# STM32G474xx register map
File version: 1.6
CPU: CM4 r0p1, little endian, MPU, FPU, 4 interrupt priority bits
Registers are 32-bit, read-write, reset 0x0 unless marked. A register's access mark holds for its fields unless they carry their own. Offsets are from the block's base; [hi:lo] are bit positions; {n}, {i} and the like mark numbered series; 'fields as' and 'values as' point back to an identical list.

## HRTIM_Common — High Resolution Timer: Common functions
Base 0x40016B80
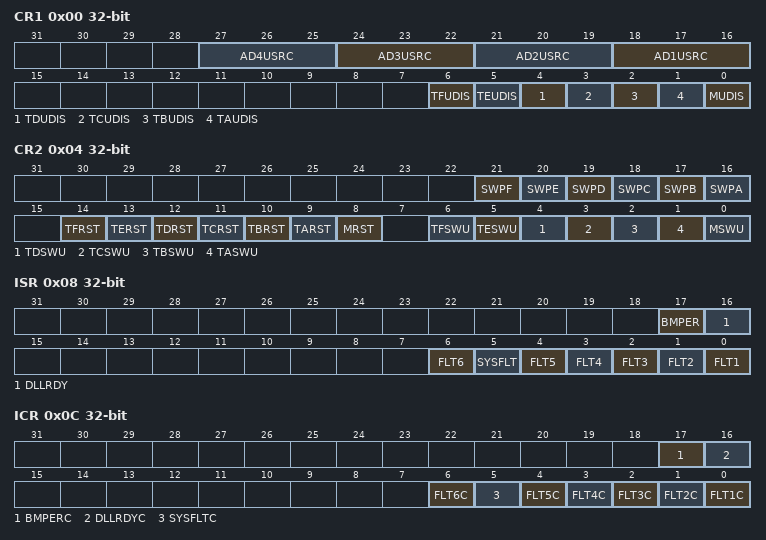
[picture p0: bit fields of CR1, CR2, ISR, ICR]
0x00 CR1 — Control Register 1
  [3n+15:3n+13] AD{n}USRC (n=1..4) — ADC Trigger {n} Update Source
  [6] TFUDIS — Timer f Update Disable
  [5] TEUDIS — Timer E Update Disable
  [4] TDUDIS — Timer D Update Disable
  [3] TCUDIS — Timer C Update Disable
  [2] TBUDIS — Timer B Update Disable
  [1] TAUDIS — Timer A Update Disable
  [0] MUDIS — Master Update Disable
0x04 CR2 — Control Register 2
  [21] SWPF — Swap Timer F outputs
  [20] SWPE — Swap Timer E outputs
  [19] SWPD — Swap Timer D outputs
  [18] SWPC — Swap Timer C outputs
  [17] SWPB — Swap Timer B outputs
  [16] SWPA — Swap Timer A outputs
  [14] TFRST — Timer f counter software reset
  [13] TERST — Timer E counter software reset
  [12] TDRST — Timer D counter software reset
  [11] TCRST — Timer C counter software reset
  [10] TBRST — Timer B counter software reset
  [9] TARST — Timer A counter software reset
  [8] MRST — Master Counter software reset
  [6] TFSWU — Timer f Software Update
  [5] TESWU — Timer E Software Update
  [4] TDSWU — Timer D Software Update
  [3] TCSWU — Timer C Software Update
  [2] TBSWU — Timer B Software Update
  [1] TASWU — Timer A Software update
  [0] MSWU — Master Timer Software update
0x08 ISR ro — Interrupt Status Register
  [17] BMPER — Burst mode Period Interrupt Flag
  [16] DLLRDY — DLL Ready Interrupt Flag
  [6] FLT6 — Fault 6 Interrupt Flag
  [5] SYSFLT — System Fault Interrupt Flag
  [n-1] FLT{n} (n=1..5) — Fault {n} Interrupt Flag
0x0C ICR wo — Interrupt Clear Register
  [17] BMPERC — Burst mode period flag Clear
  [16] DLLRDYC — DLL Ready Interrupt flag Clear
  [6] FLT6C — Fault 6 Interrupt Flag Clear
  [5] SYSFLTC — System Fault Interrupt Flag Clear
  [n-1] FLT{n}C (n=1..5) — Fault {n} Interrupt Flag Clear
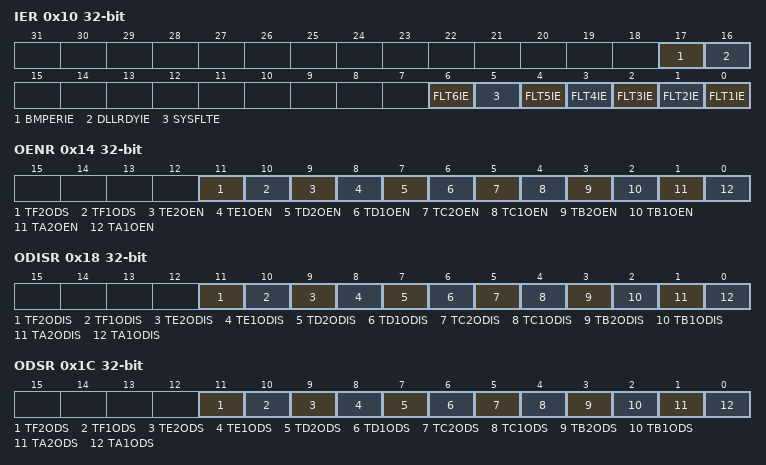
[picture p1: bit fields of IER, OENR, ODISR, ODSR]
0x10 IER — Interrupt Enable Register
  [17] BMPERIE — Burst mode period Interrupt Enable
  [16] DLLRDYIE — DLL Ready Interrupt Enable
  [6] FLT6IE — Fault 6 Interrupt Enable
  [5] SYSFLTE — System Fault Interrupt Enable
  [n-1] FLT{n}IE (n=1..5) — Fault {n} Interrupt Enable
0x14 OENR — Output Enable Register
  [11] TF2ODS — Timer F Output 2 disable status
  [10] TF1ODS — Timer F Output 1 disable status
  [9] TE2OEN — Timer E Output 2 Enable
  [8] TE1OEN — Timer E Output 1 Enable
  [7] TD2OEN — Timer D Output 2 Enable
  [6] TD1OEN — Timer D Output 1 Enable
  [5] TC2OEN — Timer C Output 2 Enable
  [4] TC1OEN — Timer C Output 1 Enable
  [3] TB2OEN — Timer B Output 2 Enable
  [2] TB1OEN — Timer B Output 1 Enable
  [1] TA2OEN — Timer A Output 2 Enable
  [0] TA1OEN — Timer A Output 1 Enable
0x18 ODISR wo
  [11] TF2ODIS, [10] TF1ODIS, [9] TE2ODIS, [8] TE1ODIS, [7] TD2ODIS, [6] TD1ODIS, [5] TC2ODIS, [4] TC1ODIS, [3] TB2ODIS, [2] TB1ODIS, [1] TA2ODIS, [0] TA1ODIS
0x1C ODSR ro — Output Disable Status Register
  [11] TF2ODS
  [10] TF1ODS
  [9] TE2ODS — Timer E Output 2 disable status
  [8] TE1ODS — Timer E Output 1 disable status
  [7] TD2ODS — Timer D Output 2 disable status
  [6] TD1ODS — Timer D Output 1 disable status
  [5] TC2ODS — Timer C Output 2 disable status
  [4] TC1ODS — Timer C Output 1 disable status
  [3] TB2ODS — Timer B Output 2 disable status
  [2] TB1ODS — Timer B Output 1 disable status
  [1] TA2ODS — Timer A Output 2 disable status
  [0] TA1ODS — Timer A Output 1 disable status
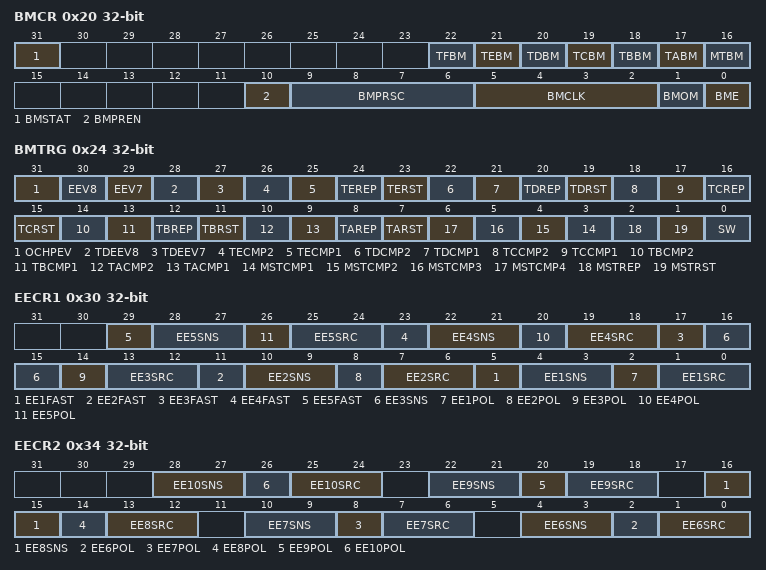
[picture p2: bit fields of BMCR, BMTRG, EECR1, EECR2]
0x20 BMCR — Burst Mode Control Register
  [31] BMSTAT — Burst Mode Status
  [22] TFBM — Timer f Burst Mode
  [21] TEBM — Timer E Burst Mode
  [20] TDBM — Timer D Burst Mode
  [19] TCBM — Timer C Burst Mode
  [18] TBBM — Timer B Burst Mode
  [17] TABM — Timer A Burst Mode
  [16] MTBM — Master Timer Burst Mode
  [10] BMPREN — Burst Mode Preload Enable
  [9:6] BMPRSC — Burst Mode Prescaler
  [5:2] BMCLK — Burst Mode Clock source
  [1] BMOM — Burst Mode operating mode
  [0] BME — Burst Mode enable
0x24 BMTRG
  [31] OCHPEV, [30] EEV8, [29] EEV7, [28] TDEEV8, [27] TDEEV7, [26] TECMP2, [25] TECMP1, [24] TEREP, [23] TERST, [22] TDCMP2, [21] TDCMP1, [20] TDREP, [19] TDRST, [18] TCCMP2, [17] TCCMP1, [16] TCREP, [15] TCRST, [14] TBCMP2, [13] TBCMP1, [12] TBREP, [11] TBRST, [10] TACMP2, [9] TACMP1, [8] TAREP, [7] TARST, [n+2] MSTCMP{n} (n=1..4), [2] MSTREP, [1] MSTRST, [0] SW
0x28 BMCMPR
  [15:0] BMCMP
0x2C BMPER — Burst Mode Period Register
  [15:0] BMPER — Burst mode Period
0x30 EECR1 — Timer External Event Control Register 1
  [6n-1] EE{n}FAST (n=1..5) — External Event {n} Fast mode
  [6n-2:6n-3] EE{n}SNS (n=1..5) — External Event {n} Sensitivity
  [6n-4] EE{n}POL (n=1..5) — External Event {n} Polarity
  [6n-5:6n-6] EE{n}SRC (n=1..5) — External Event {n} Source
0x34 EECR2 — Timer External Event Control Register 2
  [6n-32:6n-33] EE{n}SNS (n=6..10), [6n-34] EE{n}POL (n=6..10), [6n-35:6n-36] EE{n}SRC (n=6..10)
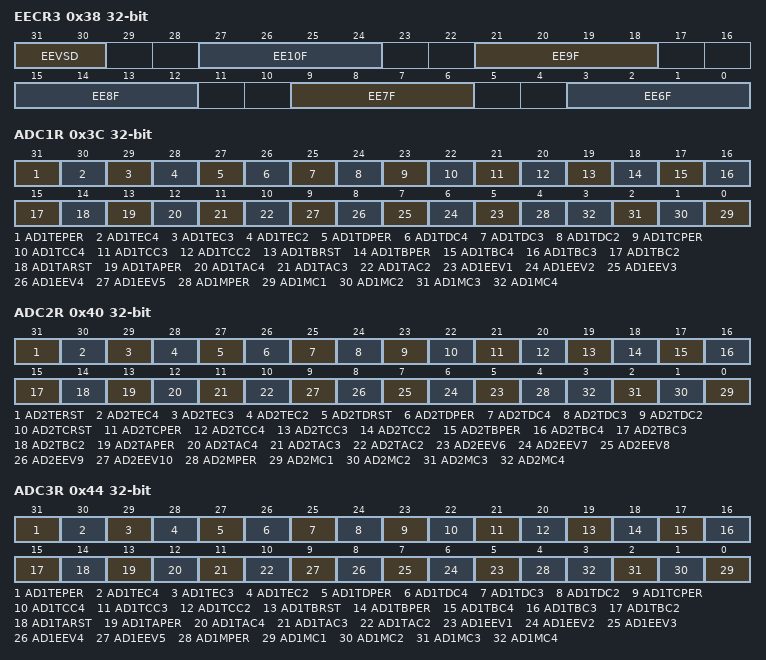
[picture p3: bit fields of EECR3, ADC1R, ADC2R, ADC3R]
0x38 EECR3 — Timer External Event Control Register 3
  [31:30] EEVSD, [6n-33:6n-36] EE{n}F (n=6..10)
0x3C ADC1R — ADC Trigger 1 Register
  [31] AD1TEPER — ADC trigger 1 on Timer E Period
  [30] AD1TEC4 — ADC trigger 1 on Timer E compare 4
  [29] AD1TEC3 — ADC trigger 1 on Timer E compare 3
  [28] AD1TEC2 — ADC trigger 1 on Timer E compare 2
  [27] AD1TDPER — ADC trigger 1 on Timer D Period
  [26] AD1TDC4 — ADC trigger 1 on Timer D compare 4
  [25] AD1TDC3 — ADC trigger 1 on Timer D compare 3
  [24] AD1TDC2 — ADC trigger 1 on Timer D compare 2
  [23] AD1TCPER — ADC trigger 1 on Timer C Period
  [22] AD1TCC4 — ADC trigger 1 on Timer C compare 4
  [21] AD1TCC3 — ADC trigger 1 on Timer C compare 3
  [20] AD1TCC2 — ADC trigger 1 on Timer C compare 2
  [19] AD1TBRST — ADC trigger 1 on Timer B Reset
  [18] AD1TBPER — ADC trigger 1 on Timer B Period
  [17] AD1TBC4 — ADC trigger 1 on Timer B compare 4
  [16] AD1TBC3 — ADC trigger 1 on Timer B compare 3
  [15] AD1TBC2 — ADC trigger 1 on Timer B compare 2
  [14] AD1TARST — ADC trigger 1 on Timer A Reset
  [13] AD1TAPER — ADC trigger 1 on Timer A Period
  [12] AD1TAC4 — ADC trigger 1 on Timer A compare 4
  [11] AD1TAC3 — ADC trigger 1 on Timer A compare 3
  [10] AD1TAC2 — ADC trigger 1 on Timer A compare 2
  [n+4] AD1EEV{n} (n=1..5) — ADC trigger 1 on External Event {n}
  [4] AD1MPER — ADC trigger 1 on Master Period
  [n-1] AD1MC{n} (n=1..4) — ADC trigger 1 on Master Compare {n}
0x40 ADC2R — ADC Trigger 2 Register
  [31] AD2TERST — ADC trigger 2 on Timer E Reset
  [30] AD2TEC4 — ADC trigger 2 on Timer E compare 4
  [29] AD2TEC3 — ADC trigger 2 on Timer E compare 3
  [28] AD2TEC2 — ADC trigger 2 on Timer E compare 2
  [27] AD2TDRST — ADC trigger 2 on Timer D Reset
  [26] AD2TDPER — ADC trigger 2 on Timer D Period
  [25] AD2TDC4 — ADC trigger 2 on Timer D compare 4
  [24] AD2TDC3 — ADC trigger 2 on Timer D compare 3
  [23] AD2TDC2 — ADC trigger 2 on Timer D compare 2
  [22] AD2TCRST — ADC trigger 2 on Timer C Reset
  [21] AD2TCPER — ADC trigger 2 on Timer C Period
  [20] AD2TCC4 — ADC trigger 2 on Timer C compare 4
  [19] AD2TCC3 — ADC trigger 2 on Timer C compare 3
  [18] AD2TCC2 — ADC trigger 2 on Timer C compare 2
  [17] AD2TBPER — ADC trigger 2 on Timer B Period
  [16] AD2TBC4 — ADC trigger 2 on Timer B compare 4
  [15] AD2TBC3 — ADC trigger 2 on Timer B compare 3
  [14] AD2TBC2 — ADC trigger 2 on Timer B compare 2
  [13] AD2TAPER — ADC trigger 2 on Timer A Period
  [12] AD2TAC4 — ADC trigger 2 on Timer A compare 4
  [11] AD2TAC3 — ADC trigger 2 on Timer A compare 3
  [10] AD2TAC2 — ADC trigger 2 on Timer A compare 2
  [n-1] AD2EEV{n} (n=6..10) — ADC trigger 2 on External Event {n}
  [4] AD2MPER — ADC trigger 2 on Master Period
  [n-1] AD2MC{n} (n=1..4) — ADC trigger 2 on Master Compare {n}
0x44 ADC3R — ADC Trigger 3 Register
  [31] AD1TEPER, [30] AD1TEC4, [29] AD1TEC3, [28] AD1TEC2, [27] AD1TDPER, [26] AD1TDC4, [25] AD1TDC3, [24] AD1TDC2, [23] AD1TCPER, [22] AD1TCC4, [21] AD1TCC3, [20] AD1TCC2, [19] AD1TBRST, [18] AD1TBPER, [17] AD1TBC4, [16] AD1TBC3, [15] AD1TBC2, [14] AD1TARST, [13] AD1TAPER, [12] AD1TAC4, [11] AD1TAC3, [10] AD1TAC2, [n+4] AD1EEV{n} (n=1..5), [4] AD1MPER, [n-1] AD1MC{n} (n=1..4)
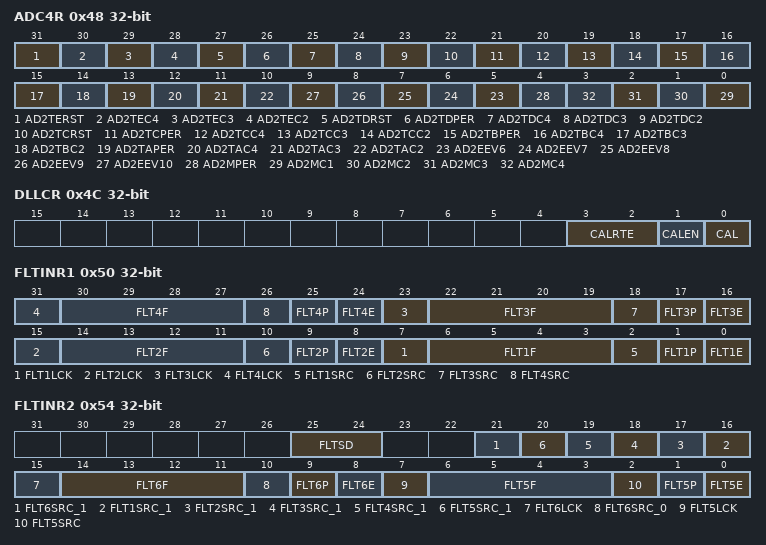
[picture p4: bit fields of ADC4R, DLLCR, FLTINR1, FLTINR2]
0x48 ADC4R — ADC Trigger 4 Register
  [31] AD2TERST, [30] AD2TEC4, [29] AD2TEC3, [28] AD2TEC2, [27] AD2TDRST, [26] AD2TDPER, [25] AD2TDC4, [24] AD2TDC3, [23] AD2TDC2, [22] AD2TCRST, [21] AD2TCPER, [20] AD2TCC4, [19] AD2TCC3, [18] AD2TCC2, [17] AD2TBPER, [16] AD2TBC4, [15] AD2TBC3, [14] AD2TBC2, [13] AD2TAPER, [12] AD2TAC4, [11] AD2TAC3, [10] AD2TAC2, [n-1] AD2EEV{n} (n=6..10), [4] AD2MPER, [n-1] AD2MC{n} (n=1..4)
0x4C DLLCR — DLL Control Register
  [3:2] CALRTE — DLL Calibration rate
  [1] CALEN — DLL Calibration Enable
  [0] CAL — DLL Calibration Start
0x50 FLTINR1 — HRTIM Fault Input Register 1
  [8n-1] FLT{n}LCK (n=1..4), [8n-2:8n-5] FLT{n}F (n=1..4), [8n-6] FLT{n}SRC (n=1..4), [8n-7] FLT{n}P (n=1..4), [8n-8] FLT{n}E (n=1..4)
0x54 FLTINR2 — HRTIM Fault Input Register 2
  [25:24] FLTSD
  [21] FLT6SRC_1 — FLT6SRC
  [n+15] FLT{n}SRC_1 (n=1..5)
  [15] FLT6LCK
  [14:11] FLT6F
  [10] FLT6SRC_0 — FLT6F
  [9] FLT6P
  [8] FLT6E
  [7] FLT5LCK
  [6:3] FLT5F
  [2] FLT5SRC
  [1] FLT5P
  [0] FLT5E
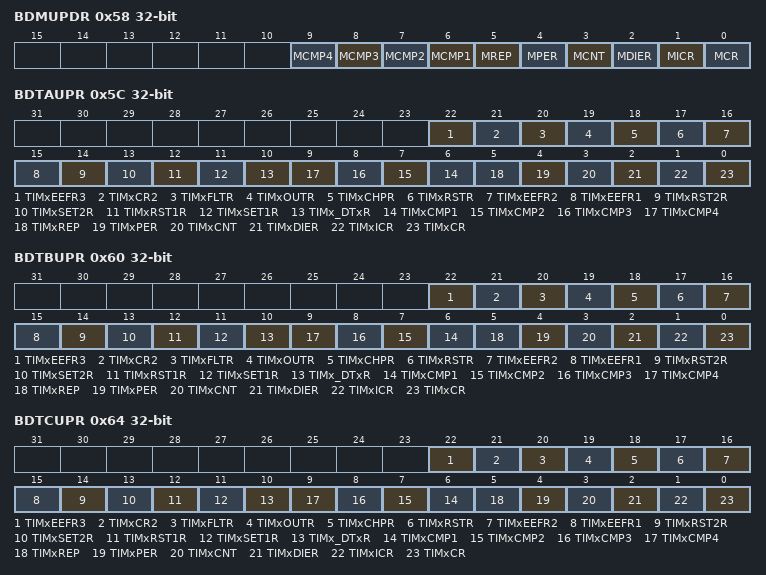
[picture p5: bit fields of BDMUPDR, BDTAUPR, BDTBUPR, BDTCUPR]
0x58 BDMUPDR
  [n+5] MCMP{n} (n=1..4), [5] MREP, [4] MPER, [3] MCNT, [2] MDIER, [1] MICR, [0] MCR
0x5C BDTAUPR — Burst DMA Timerx update Register
  [22] TIMxEEFR3
  [21] TIMxCR2
  [20] TIMxFLTR — HRTIM_FLTxR register update enable
  [19] TIMxOUTR — HRTIM_OUTxR register update enable
  [18] TIMxCHPR — HRTIM_CHPxR register update enable
  [17] TIMxRSTR — HRTIM_RSTxR register update enable
  [16] TIMxEEFR2 — HRTIM_EEFxR2 register update enable
  [15] TIMxEEFR1 — HRTIM_EEFxR1 register update enable
  [14] TIMxRST2R — HRTIM_RST2xR register update enable
  [13] TIMxSET2R — HRTIM_SET2xR register update enable
  [12] TIMxRST1R — HRTIM_RST1xR register update enable
  [11] TIMxSET1R — HRTIM_SET1xR register update enable
  [10] TIMx_DTxR — HRTIM_DTxR register update enable
  [n+5] TIMxCMP{n} (n=1..4) — HRTIM_CMP{n}xR register update enable
  [5] TIMxREP — HRTIM_REPxR register update enable
  [4] TIMxPER — HRTIM_PERxR register update enable
  [3] TIMxCNT — HRTIM_CNTxR register update enable
  [2] TIMxDIER — HRTIM_TIMxDIER register update enable
  [1] TIMxICR — HRTIM_TIMxICR register update enable
  [0] TIMxCR — HRTIM_TIMxCR register update enable
0x60 BDTBUPR — Burst DMA Timerx update Register
  fields as BDTAUPR
0x64 BDTCUPR — Burst DMA Timerx update Register
  fields as BDTAUPR
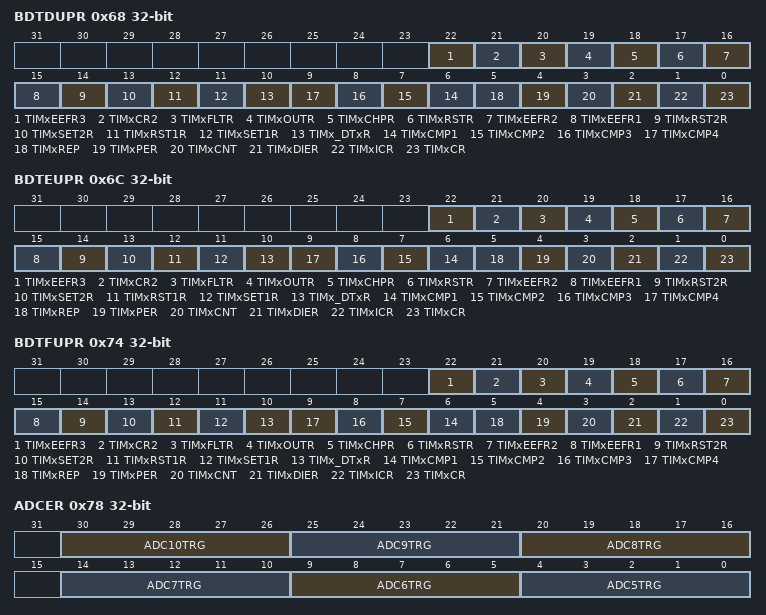
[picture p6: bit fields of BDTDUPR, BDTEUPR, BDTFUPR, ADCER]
0x68 BDTDUPR — Burst DMA Timerx update Register
  fields as BDTAUPR
0x6C BDTEUPR — Burst DMA Timerx update Register
  fields as BDTAUPR
0x70 BDMADR wo — Burst DMA Data Register
  [31:0] BDMADR — Burst DMA Data register
0x74 BDTFUPR — Burst DMA Timerx update Register
  fields as BDTAUPR
0x78 ADCER — HRTIM ADC Extended Trigger Register
  [30:26] ADC10TRG, [25:21] ADC9TRG, [20:16] ADC8TRG, [14:10] ADC7TRG, [9:5] ADC6TRG, [4:0] ADC5TRG
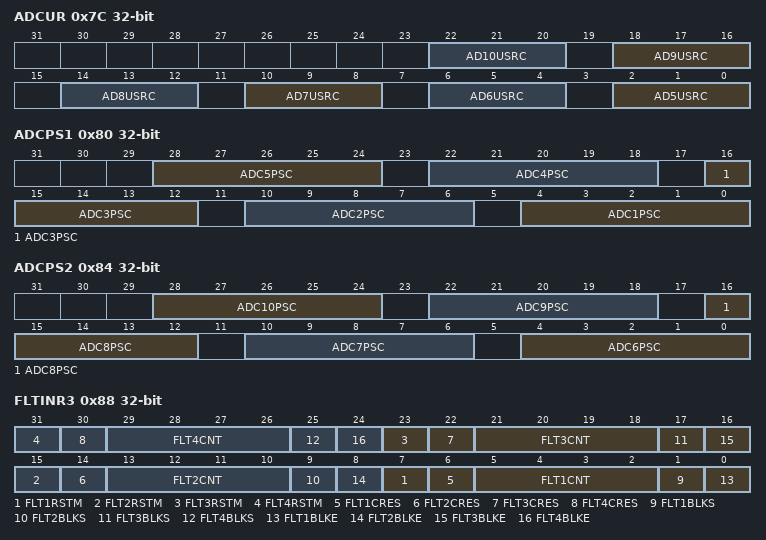
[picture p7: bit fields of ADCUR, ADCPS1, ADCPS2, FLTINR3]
0x7C ADCUR — HRTIM ADC Trigger Update Register
  [4n-18:4n-20] AD{n}USRC (n=5..10)
0x80 ADCPS1 — HRTIM ADC Post Scaler Register 1
  [6n-2:6n-6] ADC{n}PSC (n=1..5)
0x84 ADCPS2 — HRTIM ADC Post Scaler Register 2
  [6n-32:6n-36] ADC{n}PSC (n=6..10)
0x88 FLTINR3 — HRTIM Fault Input Register 3
  [8n-1] FLT{n}RSTM (n=1..4), [8n-2] FLT{n}CRES (n=1..4), [8n-3:8n-6] FLT{n}CNT (n=1..4), [8n-7] FLT{n}BLKS (n=1..4), [8n-8] FLT{n}BLKE (n=1..4)
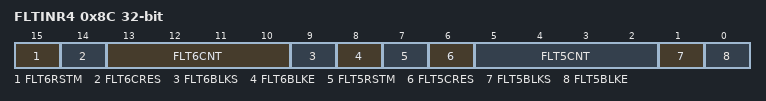
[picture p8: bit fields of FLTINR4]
0x8C FLTINR4 — HRTIM Fault Input Register 4
  [15] FLT6RSTM, [14] FLT6CRES, [13:10] FLT6CNT, [9] FLT6BLKS, [8] FLT6BLKE, [7] FLT5RSTM, [6] FLT5CRES, [5:2] FLT5CNT, [1] FLT5BLKS, [0] FLT5BLKE
